# apollo5b register map
Vendor: Ambiq Micro; Series: Apollo; File version: 1.0
CPU: CM55 r1p1, little endian, MPU, FPU, double-precision FPU, DSP, I-cache, D-cache, VTOR, ITCM, DTCM, 4 interrupt priority bits, 0 interrupts, 8 SAU regions
Registers are 32-bit, read-write, reset 0x0 unless marked. A register's access mark holds for its fields unless they carry their own. Offsets are from the block's base; [hi:lo] are bit positions.

## RTC — Real Time Clock
Base 0x40004800
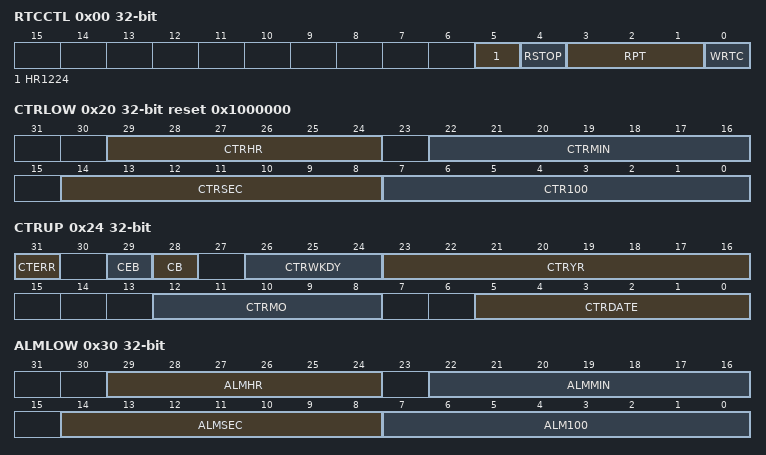
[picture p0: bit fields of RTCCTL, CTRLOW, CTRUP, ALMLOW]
0x00 RTCCTL — This is the register control for the RTC module. It enables counter writes and sets the alarm repeat interval.
  [5] HR1224 — Hours Counter mode Only 24HR mode supported
    0=24HR (Hours in 24 hour mode); 1=DISABLED (Disable the 24 hour mode)
  [4] RSTOP — RTC input clock control
    0=RUN (Allow the RTC input clock to run); 1=STOP (Stop the RTC input clock)
  [3:1] RPT — Alarm repeat interval
    0=DIS (Alarm interrupt disabled); 1=YEAR (Interrupt every year); 2=MONTH (Interrupt every month); 3=WEEK (Interrupt every week); 4=DAY (Interrupt every day); 5=HR (Interrupt every hour); 6=MIN (Interrupt every minute); 7=SEC (Interrupt every second/10th/100th)
  [0] WRTC — Counter write control
    0=DIS (Counter writes are disabled); 1=EN (Counter writes are enabled)
0x04 RTCSTAT — This is the register status for the RTC module.
  [0] WRITEBUSY — Indicates that an RTC update (write) is still in progress. Writes are initiated by writing the CTTLOW register - CTRUP must be written before CTRLOW to be updated (otherwise it will retain its current value)
0x20 CTRLOW reset 0x1000000 — This counter contains the values for hour, minutes, seconds and 100ths of a second Counter.
  [29:24] CTRHR — Hours Counter. Contains the current value for hour.
  [22:16] CTRMIN — Minutes Counter. Contains the current value for minutes.
  [14:8] CTRSEC — Seconds Counter. Contains the current value for seconds.
  [7:0] CTR100 — 100ths of a second Counter. Contains the current value for hundredths of a second.
0x24 CTRUP — This register contains the day, month and year information. It contains which day in the week, and the century as well. The information of the century can also be derived from the year information. The 31st bit contains the error bit. See description in the register bit for condition when error is triggered.
  [31] CTERR — Counter read error status. Error is triggered when software reads the lower word of the counters, and fails to read the upper counter within 1/100 second. This is because when the lower counter is read, the upper counter is held off from incrementing until it is read so that the full time stamp can be read.
    0=NOERR (No read error occurred); 1=RDERR (Read error occurred)
  [29] CEB — Century enable
    0=DIS (Disable the Century bit from changing); 1=EN (Enable the Century bit to change)
  [28] CB — Century Bit. This bit will be toggled when the Years register rolls over from 99 to 00 if the CEB bit is a 1. CB=0 assumes the century it 19xx or 21xx, and CB=1 assumes it is 20xx for leap year calculations.
    0=Century is 2000s; 1=1900_2100 (Century is 1900s/2100s)
  [26:24] CTRWKDY — Weekdays Counter. Contains the current value for weekdays.
  [23:16] CTRYR — Years Counter. Contains the current value for year.
  [12:8] CTRMO — Months Counter. Contains the current value for months.
  [5:0] CTRDATE — Date Counter. Contains the current value for date.
0x30 ALMLOW — This register is the Alarm settings for hours, minutes, second and 1/100th seconds settings.
  [29:24] ALMHR — Hours Alarm. Contains the current value for hour alarm.
  [22:16] ALMMIN — Minutes Alarm. Contains the current value for minute alarm.
  [14:8] ALMSEC — Seconds Alarm. Contains the current value for second alarm.
  [7:0] ALM100 — 100ths of a second Alarm. Contains the current value for hundredths of a second alarm.
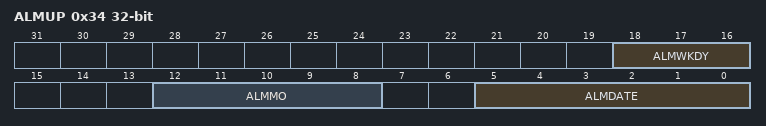
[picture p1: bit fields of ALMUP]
0x34 ALMUP — This register is the alarm settings for week, month and day.
  [18:16] ALMWKDY — Weekdays Alarm. Contains the current value for weekdays alarm.
  [12:8] ALMMO — Months Alarm. Contains the current value for months alarm.
  [5:0] ALMDATE — Date Alarm. Contains the current value for date alarm.
0x200 INTEN — Set bits in this register to allow this module to generate the corresponding interrupt.
  [0] ALM — RTC Alarm interrupt
0x204 INTSTAT — Read bits from this register to discover the cause of a recent interrupt.
  [0] ALM — RTC Alarm interrupt
0x208 INTCLR — Write a 1 to a bit in this register to clear the interrupt status associated with that bit.
  [0] ALM — RTC Alarm interrupt
0x20C INTSET — Write a 1 to a bit in this register to instantly generate an interrupt from this module. (Generally used for testing purposes).
  [0] ALM — RTC Alarm interrupt
